AUTOSAR XML (schema 4-3-0)
package /ComponentTypes
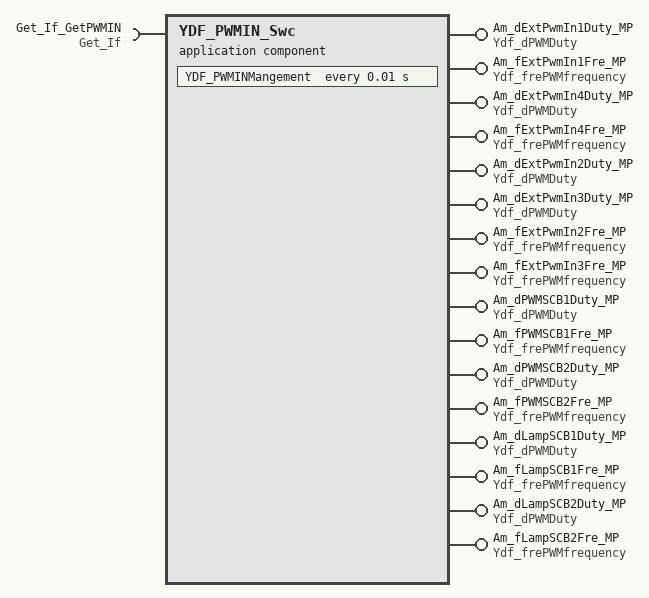
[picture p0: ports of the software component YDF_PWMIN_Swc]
  application sw component type YDF_PWMIN_Swc
    4 x provide port:
      Am_dExtPwmIn1Duty_MP: nonqueued-sender-com-spec{data-element=PWMDuty, init-value=0}, provided-interface=Ydf_dPWMDuty
      Am_fExtPwmIn1Fre_MP: nonqueued-sender-com-spec{data-element=PWMfrequency, init-value=0}, provided-interface=Ydf_frePWMfrequency
      Am_dExtPwmIn4Duty_MP: nonqueued-sender-com-spec{data-element=PWMDuty, init-value=0}, provided-interface=Ydf_dPWMDuty
      Am_fExtPwmIn4Fre_MP: nonqueued-sender-com-spec{data-element=PWMfrequency, init-value=0}, provided-interface=Ydf_frePWMfrequency
    require port Get_If_GetPWMIN: required-interface=Get_If
      required-com-specs:
        Get_Ad_Result
        Get_io_inResult
        Get_BTS_OutResult
        Get_CAN_ActiveInf
        Icu_17_GtmCcu6_PWMIN_CH{1..4}
        Icu_17_GtmCcu6_PWMIN_PWMSCB1
        Icu_17_GtmCcu6_PWMIN_PWMSCB2
        Icu_17_GtmCcu6_PWMIN_LAMPSCB1
        Icu_17_GtmCcu6_PWMIN_LAMPSCB2
        Get_Bottom_Ver
        Get_SentData
        Get_Level_OutResult
        Get_PwmOrLevel_OutResult
        Get_Motor_OutResult
    12 x provide port:
      Am_dExtPwmIn2Duty_MP: nonqueued-sender-com-spec{data-element=PWMDuty, init-value=0}, provided-interface=Ydf_dPWMDuty
      Am_dExtPwmIn3Duty_MP: nonqueued-sender-com-spec{data-element=PWMDuty, init-value=0}, provided-interface=Ydf_dPWMDuty
      Am_fExtPwmIn2Fre_MP: nonqueued-sender-com-spec{data-element=PWMfrequency, init-value=0}, provided-interface=Ydf_frePWMfrequency
      Am_fExtPwmIn3Fre_MP: nonqueued-sender-com-spec{data-element=PWMfrequency, init-value=0}, provided-interface=Ydf_frePWMfrequency
      Am_dPWMSCB1Duty_MP: nonqueued-sender-com-spec{data-element=PWMDuty, init-value=0}, provided-interface=Ydf_dPWMDuty
      Am_fPWMSCB1Fre_MP: nonqueued-sender-com-spec{data-element=PWMfrequency, init-value=0}, provided-interface=Ydf_frePWMfrequency
      Am_dPWMSCB2Duty_MP: nonqueued-sender-com-spec{data-element=PWMDuty, init-value=0}, provided-interface=Ydf_dPWMDuty
      Am_fPWMSCB2Fre_MP: nonqueued-sender-com-spec{data-element=PWMfrequency, init-value=0}, provided-interface=Ydf_frePWMfrequency
      Am_dLampSCB1Duty_MP: nonqueued-sender-com-spec{data-element=PWMDuty, init-value=0}, provided-interface=Ydf_dPWMDuty
      Am_fLampSCB1Fre_MP: nonqueued-sender-com-spec{data-element=PWMfrequency, init-value=0}, provided-interface=Ydf_frePWMfrequency
      Am_dLampSCB2Duty_MP: nonqueued-sender-com-spec{data-element=PWMDuty, init-value=0}, provided-interface=Ydf_dPWMDuty
      Am_fLampSCB2Fre_MP: nonqueued-sender-com-spec{data-element=PWMfrequency, init-value=0}, provided-interface=Ydf_frePWMfrequency
    behavior YDF_PWMIN_Swc_InternalBehavior
      timing event TMT_YDF_PWMINMangement: start-on-event=YDF_PWMINMangement, period=0.01
      runnable YDF_PWMINMangement
        data-send-points:
          16 x access:
            SEND_Am_dExtPwmIn{1..4}Duty_MP_PWMDuty: accessed-variable=Am_dExtPwmIn{1..4}Duty_MP.PWMDuty
            SEND_Am_dLampSCB1Duty_MP_PWMDuty: accessed-variable=Am_dLampSCB1Duty_MP.PWMDuty
            SEND_Am_dLampSCB2Duty_MP_PWMDuty: accessed-variable=Am_dLampSCB2Duty_MP.PWMDuty
            SEND_Am_dPWMSCB1Duty_MP_PWMDuty: accessed-variable=Am_dPWMSCB1Duty_MP.PWMDuty
            SEND_Am_dPWMSCB2Duty_MP_PWMDuty: accessed-variable=Am_dPWMSCB2Duty_MP.PWMDuty
            SEND_Am_fExtPwmIn{2..4}Fre_MP_PWMfrequency: accessed-variable=Am_fExtPwmIn{2..4}Fre_MP.PWMfrequency
            SEND_Am_fLampSCB1Fre_MP_PWMfrequency: accessed-variable=Am_fLampSCB1Fre_MP.PWMfrequency
            SEND_Am_fLampSCB2Fre_MP_PWMfrequency: accessed-variable=Am_fLampSCB2Fre_MP.PWMfrequency
            SEND_Am_fPWMSCB1Fre_MP_PWMfrequency: accessed-variable=Am_fPWMSCB1Fre_MP.PWMfrequency
            SEND_Am_fPWMSCB2Fre_MP_PWMfrequency: accessed-variable=Am_fPWMSCB2Fre_MP.PWMfrequency
            SEND_Am_fPwmIn1Fre_MP_PWMfrequency: accessed-variable=Am_fExtPwmIn1Fre_MP.PWMfrequency
        8 x sync call:
          SC_Get_If_GetPWMIN_Icu_17_GtmCcu6_PWMIN_CH{1..4}: operation=Get_If_GetPWMIN.Icu_17_GtmCcu6_PWMIN_CH{1..4}
          SC_Get_If_GetPWMIN_Icu_17_GtmCcu6_PWMIN_LAMPSCB1: operation=Get_If_GetPWMIN.Icu_17_GtmCcu6_PWMIN_LAMPSCB1
          SC_Get_If_GetPWMIN_Icu_17_GtmCcu6_PWMIN_LAMPSCB2: operation=Get_If_GetPWMIN.Icu_17_GtmCcu6_PWMIN_LAMPSCB2
          SC_Get_If_GetPWMIN_Icu_17_GtmCcu6_PWMIN_PWMSCB1: operation=Get_If_GetPWMIN.Icu_17_GtmCcu6_PWMIN_PWMSCB1
          SC_Get_If_GetPWMIN_Icu_17_GtmCcu6_PWMIN_PWMSCB2: operation=Get_If_GetPWMIN.Icu_17_GtmCcu6_PWMIN_PWMSCB2
  swc implementation YDF_PWMIN_Swc_Implementation: behavior=YDF_PWMIN_Swc_InternalBehavior
